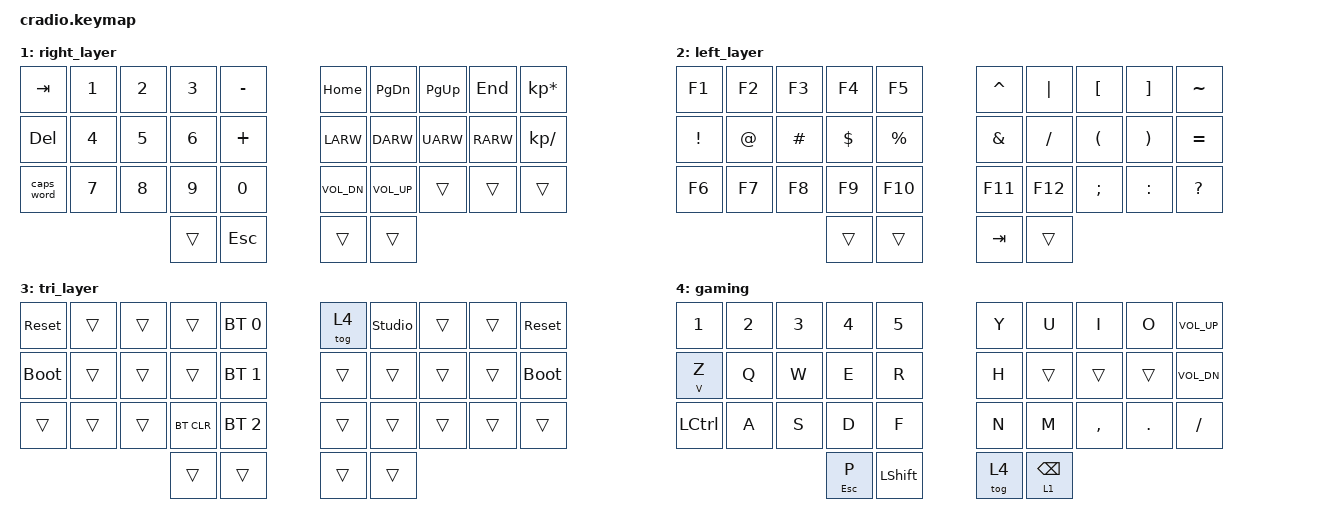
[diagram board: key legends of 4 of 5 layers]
// Copyright (c) 2022 The ZMK Contributors
// SPDX-License-Identifier: MIT

#include <behaviors.dtsi>
#include <dt-bindings/zmk/keys.h>
#include <dt-bindings/zmk/bt.h>

// Home row mods macro
#define HRML(k1,k2,k3) &ht LALT k1  &ht LCTRL k2  &ht LGUI k3
#define HRMR(k1,k2,k3,k4) &ht RGUI k1  &ht RCTRL k2  &ht RALT k3  &ht RSHFT k4

//#define GAME 4

/ {
    behaviors {
        ht: hold_tap {
            compatible = "zmk,behavior-hold-tap";
            #binding-cells = <2>;
            flavor = "tap-preferred";
            tapping-term-ms = <220>;
            quick-tap-ms = <150>;
            require-prior-idle-ms = <100>;
            bindings = <&kp>, <&kp>;
        };
        td1: tap_dance1 {
            compatible = "zmk,behavior-tap-dance";
            #binding-cells = <0>;
            tapping-term-ms = <200>;
            bindings = <&kp O>, <&nordic2>;
        };
        td_mt: tap_dance_mod_tap {
            compatible = "zmk,behavior-tap-dance";
            #binding-cells = <0>;
            tapping-term-ms = <200>;
            bindings = <&mt LSHIFT A>, <&nordic1>;
        };
    };

    macros {
        nordic1: nordic1 {
            compatible = "zmk,behavior-macro";
            #binding-cells = <0>;
            bindings
                = <&macro_press &kp RALT>
                , <&macro_tap &kp Q>
                , <&macro_release &kp RALT>
                ;
        };
        nordic2: nordic2 {
            compatible = "zmk,behavior-macro";
            #binding-cells = <0>;
            bindings
                = <&macro_press &kp RALT>
                , <&macro_tap &kp P>
                , <&macro_release &kp RALT>
                ;
        };
    };
    combos {
        compatible = "zmk,combos";
        combo_bkspc {
            timeout-ms = <50>;
            key-positions = <17 18>;
            bindings = <&kp BSPC>;
        };
        combo_del {
            timeout-ms = <50>;
            key-positions = <7 8>;
            bindings = <&kp DEL>;
        };
        combo_tab {
            timeout-ms = <50>;
            key-positions = <11 12>;
            bindings = <&kp TAB>;
        };
        combo_caps {
            timeout-ms = <50>;
            key-positions = <21 22>;
            bindings = <&caps_word>;
        };
        combo_nordic_o {
            timeout-ms = <50>;
            key-positions = <8 9>;
            bindings = <&kp RA(P)>;
        };
        combo_nordic_a {
            timeout-ms = <50>;
            key-positions = <18 19>;
            bindings = <&kp RA(Q)>;
        };
    };

    conditional_layers {
        compatible = "zmk,conditional-layers";
        tri_layer {
            if-layers = <1 2>;
            then-layer = <3>;
        };
    };

    keymap {
        compatible = "zmk,keymap";
        default_layer {
            bindings = <
        //╭──────────┬──────────┬──────────┬──────────┬──────────╮   ╭──────────┬──────────┬──────────┬──────────┬──────────╮
        //│  Q       │  W       │  E       │  R       │  T       │   │  Y       │  U       │  I       │  O       │  P       │
            &kp Q      &kp W      &kp E      &kp R      &kp T          &kp Y      &kp U      &kp I      &kp O      &kp P
        //├──────────┼──────────┼──────────┼──────────┼──────────┤   ├──────────┼──────────┼──────────┼──────────┼──────────┤
        //│ A        │  S       │  D       │  F       │  G       │   │  H       │  J       │  K       │  L       │ ' "      │
           &kp A      HRML(S,         D,         F)       &kp G          &kp H      HRMR(J,      K,         L,        SQT)
        //├──────────┼──────────┼──────────┼──────────┼──────────┤   ├──────────┼──────────┼──────────┼──────────┼──────────┤
        //│  Z       │  X       │  C       │  V       │  B       │   │  N       │  M       │ , <      │ . >      │ - _      │
            &kp Z      &kp X      &kp C      &kp V      &kp B          &kp N      &kp M      &kp COMMA  &kp DOT    &kp MINUS
        //╰──────────┴──────────┴──────────┼──────────┼──────────┤   ├──────────┼──────────┼──────────┴──────────┴──────────╯
                                            &lt 2 ENTER &mt LSHFT ESC    &kp SPACE  &lt 1 BSPC
        //                                 ╰──────────┴──────────╯   ╰──────────┴──────────╯
            >;
        };

        right_layer {
            bindings = <
        //╭──────────┬──────────┬──────────┬──────────┬──────────╮   ╭──────────┬──────────┬──────────┬──────────┬──────────╮
        //│ TAB      │  1       │  2       │  3       │          │   │ HOME     │ PAGE DN  │ PAGE UP  │ END      │  *       │
           &kp TAB    &kp N1     &kp N2     &kp N3     &kp MINUS      &kp HOME   &kp PG_DN  &kp PG_UP  &kp END    &kp KP_MULTIPLY
        //├──────────┼──────────┼──────────┼──────────┼──────────┤   ├──────────┼──────────┼──────────┼──────────┼──────────┤
        //│ DELETE   │  4       │  5       │  6       │          │   │ LEFT     │ DOWN     │ UP       │ RIGHT    │  /       │
            &kp DEL    &kp N4     &kp N5     &kp N6     &kp PLUS      &kp LARW   &kp DARW   &kp UARW   &kp RARW   &kp KP_DIVIDE
        //├──────────┼──────────┼──────────┼──────────┼──────────┤   ├──────────┼──────────┼──────────┼──────────┼──────────┤
        //│ CAPS     │  7       │  8       │  9       │  0       │   │          │          │          │          │          │
           &caps_word &kp N7     &kp N8     &kp N9     &kp N0     &kp C_VOL_DN &kp C_VOL_UP  &trans     &trans     &trans
        //╰──────────┴──────────┴──────────┼──────────┼──────────┤   ├──────────┼──────────┼──────────┴──────────┴──────────╯
                                            &trans     &kp ESC         &trans     &trans
        //                                 ╰──────────┴──────────╯   ╰──────────┴──────────╯
            >;
        };

        left_layer {
            bindings = <
        //╭──────────┬──────────┬──────────┬──────────┬──────────╮   ╭──────────┬──────────┬──────────┬──────────┬──────────╮
        //│    F1    │    F2    │    F3    │    F4    │    F5    │   │  ^       │  PIPE    │  [       │  ]       │  ~       │
            &kp F1    &kp F2     &kp F3     &kp F4     &kp F5          &kp CARET  &kp PIPE  &kp LBKT   &kp RBKT   &kp TILDE
        //├──────────┼──────────┼──────────┼──────────┼──────────┤   ├──────────┼──────────┼──────────┼──────────┼──────────┤
        //│  !       │  @       │  #       │  $       │  %       │   │  &       │  FSLH    │  (       │  )       │  =       │
           &kp EXCL   &kp AT     &kp HASH   &kp DLLR   &kp PRCNT      &kp AMPS   &kp FSLH   &kp LPAR   &kp RPAR   &kp EQUAL
        //├──────────┼──────────┼──────────┼──────────┼──────────┤   ├──────────┼──────────┼──────────┼──────────┼──────────┤
        //│    F6    │    F7    │    F8    │    F9    │    F10   │   │    F11   │    F12   │  ;       │  :       │   ?      │
            &kp F6    &kp F7     &kp F8     &kp F9     &kp F10        &kp F11    &kp F12  &kp SEMI   &kp COLON  &kp QMARK 
        //╰──────────┴──────────┴──────────┼──────────┼──────────┤   ├──────────┼──────────┼──────────┴──────────┴──────────╯
                                            &trans     &trans         &kp TAB      &trans
        //                                 ╰──────────┴──────────╯   ╰──────────┴──────────╯
            >;
        };

        tri_layer {
            bindings = <
        //╭──────────┬──────────┬──────────┬──────────┬──────────╮   ╭──────────┬──────────┬──────────┬──────────┬──────────╮
        //│ RESET    │          │          │          │PROFILE 0 │   │          │          │          │          │  RESET   │
           &sys_reset  &trans     &trans     &trans    &bt BT_SEL 0   &tog 4   &studio_unlock &trans     &trans    &sys_reset
        //├──────────┼──────────┼──────────┼──────────┼──────────┤   ├──────────┼──────────┼──────────┼──────────┼──────────┤
        //│BOOTLOADER│          │          │          │PROFILE 1 │   │          │          │          │          │BOOTLOADER│
          &bootloader  &trans     &trans     &trans    &bt BT_SEL 1    &trans     &trans     &trans     &trans    &bootloader
        //├──────────┼──────────┼──────────┼──────────┼──────────┤   ├──────────┼──────────┼──────────┼──────────┼──────────┤
        //│          │          │          │ CLEAR BT │PROFILE 2 │   │          │          │          │          │          │
            &trans     &trans     &trans    &bt BT_CLR &bt BT_SEL 2    &trans     &trans     &trans     &trans     &trans
        //╰──────────┴──────────┴──────────┼──────────┼──────────┤   ├──────────┼──────────┼──────────┴──────────┴──────────╯
                                             &trans     &trans         &trans     &trans
        //                                 ╰──────────┴──────────╯   ╰──────────┴──────────╯
            >;
        };

        gaming {
            bindings = <
        //╭──────────┬──────────┬──────────┬──────────┬──────────╮   ╭──────────┬──────────┬──────────┬──────────┬──────────╮
        //│    1     │     2    │     3    │     4    │     5    │   │  Y       │  U       │  I       │  O       │          │
           &kp N1      &kp N2    &kp N3     &kp N4     &kp N5         &kp Y      &kp U      &kp I      &kp O      &kp C_VOL_UP
        //├──────────┼──────────┼──────────┼──────────┼──────────┤   ├──────────┼──────────┼──────────┼──────────┼──────────┤
        //│   V      │     Q    │     W    │     E    │     R    │   │  H       │  J       │  K       │  L       │          │
           &mt V Z    &kp Q      &kp W      &kp E      &kp R          &kp H      &trans     &trans     &trans     &kp C_VOL_DN
        //├──────────┼──────────┼──────────┼──────────┼──────────┤   ├──────────┼──────────┼──────────┼──────────┼──────────┤
        //│   CTRL   │    A     │     S    │    D     │     F    │   │  N       │  M       │ , <      │ . >      │ / ?      │
           &kp LCTRL  &kp A      &kp S      &kp D      &kp  F         &kp N      &kp M      &kp COMMA  &kp DOT    &kp FSLH
        //╰──────────┴──────────┴──────────┼──────────┼──────────┤   ├──────────┼──────────┼──────────┴──────────┴──────────╯
        //                                 │    P     │   SHIFT  │   │          │          │
                                            &mt ESC P  &kp LSHFT      &tog 4     &lt 1 BSPC
        //                                 ╰──────────┴──────────╯   ╰──────────┴──────────╯
            >;
        };
    };
};
